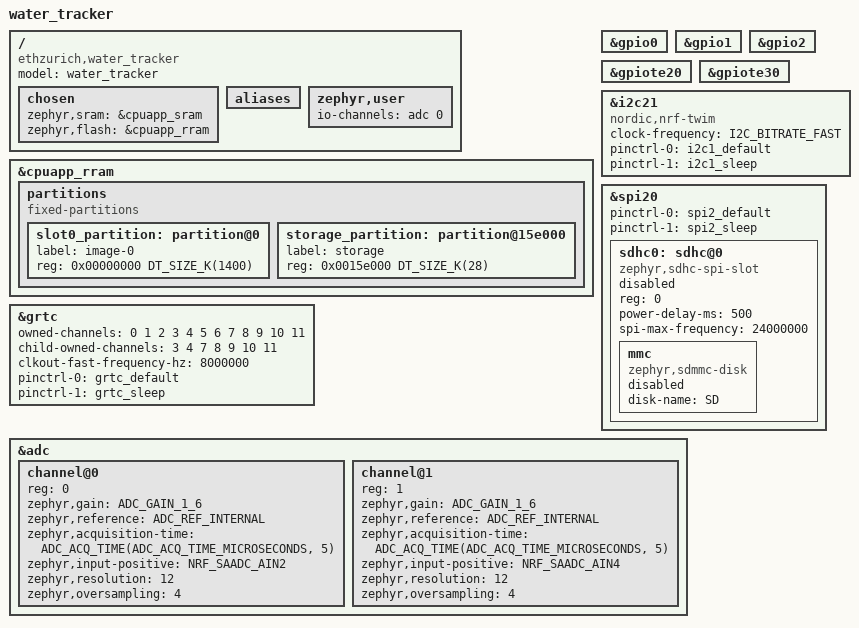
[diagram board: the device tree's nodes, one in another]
/*
 * Water sense board — ISP2454-LX (Nordic nRF54L15) + VL53L9CX + SD card.
 *
 * Migrated 2026-09-04 from Victor's hardware-model-v1 board file, for nRF
 * Connect SDK v3.3. The original is recoverable at commit ec65298.
 *
 * ---------------------------------------------------------------------------
 * WHAT SURVIVED UNCHANGED: every pin Victor assigned, the ADC configuration,
 * the BT_CTLR default, and the intent of the SPI/SD arrangement.
 *
 * WHAT CHANGED, and why:
 *   - hardware model v1 -> v2 (the reason nothing built under NCS 3.3)
 *   - nrf54L15_M33.dtsi -> nrf54l15_cpuapp.dtsi, and the SoC symbol with it
 *   - flash0/sram0 -> cpuapp_rram/cpuapp_sram; the nRF54L15 has RRAM
 *   - partitions resized from 512 KB to the full 1428 KB, MCUboot dropped
 *   - gpio1 and gpio2 enabled (where the pins actually are), gpio0 too
 *   - AP_CLK: 8 MHz on P0.00 from GRTC clkout-fast, not PWM
 *   - RTT console added, so the board can say something
 *   - sdhc0 disabled pending the chip-select decision — see the note on it
 *
 * PERIPHERAL INSTANCE NAMES ARE THE REMAINING GUESS. The nRF54L15 numbers by
 * power domain. i2c21 and spi20 below are chosen to match the pin domains
 * (P1 -> 20-series, P2 -> the fast domain), but if the build says a node does
 * not exist, diff against zephyr/boards/nordic/nrf54l15dk/ in the installed
 * SDK — that is the authority, and it settles every name here at once.
 * ---------------------------------------------------------------------------
 *
 * SPDX-License-Identifier: Apache-2.0
 */

/dts-v1/;

#include <nordic/nrf54l15_cpuapp.dtsi>
#include <zephyr/dt-bindings/adc/adc.h>
#include <zephyr/dt-bindings/gpio/gpio.h>
#include <zephyr/dt-bindings/i2c/i2c.h>
#include "water_sense_board_nrf54l15_cpuapp-pinctrl.dtsi"

/ {
	model = "water_tracker";
	compatible = "ethzurich,water_tracker";

	chosen {
		zephyr,sram = &cpuapp_sram;
		zephyr,flash = &cpuapp_rram;

		/*
		 * Console over SEGGER RTT, not a UART.
		 *
		 * No UART pins are assigned on this board and the pin budget is
		 * already committed, so RTT costs nothing and works over the
		 * J-Link that is attached anyway. Swap for a UART later if the
		 * pins appear.
		 *
		 * NO zephyr,code-partition: without MCUboot in the build it
		 * would link the image at a bootloader offset the chip never
		 * jumps to, which looks exactly like a dead board. Add it back
		 * together with sysbuild and MCUboot, not before.
		 */
	};

	aliases {
		/*
		 * watchdog0 = &wdt0 was in the original and is dropped: wdt0
		 * does not exist on this SoC (the instances are numbered by
		 * domain, wdt30/wdt31). Nothing referenced it. Re-add pointing
		 * at the real instance if a watchdog is wanted.
		 */
	};

	zephyr,user {
		io-channels = <&adc 0>;
	};
};

/* ---------------------------------------------------------------------------
 * Memory. 1428 KB is what the application core actually has — the remainder of
 * the nRF54L15's RRAM is reserved for the FLPR core. The previous table mapped
 * 512 KB of it and left the other two thirds stranded.
 *
 * No bootloader here, so the application gets everything up to the storage
 * area. Adding MCUboot later is a partition change and a rebuild, not a
 * redesign — the four-partition layout is in
 * docs/hardware/water-sense-board-review.md.
 * -------------------------------------------------------------------------*/
&cpuapp_rram {
	partitions {
		compatible = "fixed-partitions";
		#address-cells = <1>;
		#size-cells = <1>;

		slot0_partition: partition@0 {
			label = "image-0";
			reg = <0x00000000 DT_SIZE_K(1400)>;
		};

		storage_partition: partition@15e000 {
			label = "storage";
			reg = <0x0015e000 DT_SIZE_K(28)>;
		};
	};
};

/* All three ports enabled.
 *
 * gpio2 is the one that matters: chip select on P2.05 is driven in software
 * from the port file, and a software-driven pin needs the GPIO driver even
 * though pinctrl signals do not. gpio1 and gpio0 carry only pinctrl signals
 * (the I2C bus and AP_CLK respectively) and would work without this, but there
 * is no reason to leave ports off on a board still being brought up.
 */
&gpio0 {
	status = "okay";
};

&gpio1 {
	status = "okay";
};

&gpio2 {
	status = "okay";
};

&gpiote20 {
	status = "okay";
};

&gpiote30 {
	status = "okay";
};

/* ---------------------------------------------------------------------------
 * AP_CLK for the VL53L9CX — 8 MHz on P0.00, from the GRTC fast clock output.
 *
 * P0.13 was given first and is not a pin on this SoC (gpio0 has ngpios = <7>,
 * so P0.00..P0.06). Corrected to P0.00 by Victor. That correction also forces
 * the mechanism: PWM cannot drive port 0, so this is GRTC, not pwm20.
 *
 * WHY THIS IS BETTER THAN THE PWM IT REPLACES. From
 * zephyr/drivers/timer/nrf_grtc_timer.c:
 *
 *     grtc_div = base_frequency / (requested_frequency * 2)
 *     #error if requested > base / 2
 *
 * with base = pclk = 16 MHz. So the maximum fast-clock output is 8 MHz, and at
 * 8 MHz the divider is exactly 1. Our frequency is the top of the range and
 * lands on an integer divider — none of the COUNTERTOP-of-2 marginality that
 * made 8 MHz a stretch on a PWM.
 *
 * It is also the ONLY usable value: the next divider down gives 4 MHz, which
 * is below the sensor's 6 MHz minimum. The constraint picked the number again,
 * independently of the PWM reasoning that first arrived at it.
 *
 * ONE CONSEQUENCE FOR STAGE 4, and it is a real trade rather than a detail:
 * the GRTC clock output is configured once at boot and runs continuously.
 * Zephyr exposes no runtime gate for it, so AP_CLK can no longer be switched
 * off with the sensor power domain the way the driver was designed to. Either
 * accept an always-on 8 MHz output and measure what it costs, or move AP_CLK
 * to a P1/P2 pin on a PWM, which is gateable but marginal at 8 MHz. Worth
 * deciding with the Power Profiler rather than in advance.
 * -------------------------------------------------------------------------*/
&grtc {
	/* status = "okay" is not optional and is not about AP_CLK: the GRTC is
	 * this SoC's system timer, and the SoC dtsi ships it disabled. Without
	 * this line CONFIG_SYS_CLOCK_HW_CYCLES_PER_SEC is never defined and the
	 * build fails deep inside sys/clock.h with "operator '==' has no left
	 * operand", which names nothing useful. The original board file did not
	 * enable it either — it simply never got far enough to find out.
	 */
	status = "okay";

	/* Which of the 12 capture/compare channels this core owns, and which it
	 * lends to the FLPR core and to Zero Latency IRQs. The GRTC timer driver
	 * #errors without them. Values taken from Nordic's own
	 * nrf54l_05_10_15_cpuapp_common.dtsi — channels 7-11 for ZLI, 3-4 for
	 * FLPR — and worth revisiting only if the FLPR core is ever used here.
	 */
	owned-channels = <0 1 2 3 4 5 6 7 8 9 10 11>;
	child-owned-channels = <3 4 7 8 9 10 11>;

	clkout-fast-frequency-hz = <8000000>;
	pinctrl-0 = <&grtc_default>;
	pinctrl-1 = <&grtc_sleep>;
	pinctrl-names = "default", "sleep";
};

/* I2C: SCL P1.08, SDA P1.13. Instance renamed from i2c1, which does not exist
 * on this SoC.
 *
 * 400 kHz rather than the default 100 kHz: a full 54x42 VL53L9CX frame is
 * 14,842 bytes, which is ~404 ms at 400 kHz and ~1.6 s at 100 kHz.
 *
 * If the board has no external pull-ups on SDA/SCL, add bias-pull-up to the
 * pinctrl group — it is silent either way until the bus does not work.
 */
&i2c21 {
	status = "okay";
	compatible = "nordic,nrf-twim";
	clock-frequency = <I2C_BITRATE_FAST>;

	pinctrl-0 = <&i2c1_default>;
	pinctrl-1 = <&i2c1_sleep>;
	pinctrl-names = "default", "sleep";

	/* The VL53L9CX node is NOT here on purpose. It belongs in an
	 * application-level overlay, so this board file stays about the board
	 * and the sensor's configuration travels with the application that
	 * uses it.
	 */
};

/* SPI to the SD card: SCK P2.01, MOSI/SDI P2.04, MISO/SDO P2.02.
 * Instance renamed from spi2, which does not exist on this SoC.
 */
&spi20 {
	status = "okay";
	pinctrl-0 = <&spi2_default>;
	pinctrl-1 = <&spi2_sleep>;
	pinctrl-names = "default", "sleep";

	/*
	 * DISABLED PENDING A DECISION, not deleted.
	 *
	 * Chip select on P2.05 is driven in software from the port file. This
	 * node is Zephyr's SD-over-SPI stack, and `reg = <0>` means "SPI device
	 * 0" — it expects the controller's cs-gpios[0] to exist and drives it
	 * around every transfer. The two cannot both own the pin: manual
	 * toggling underneath Zephyr's produces glitches that read as card
	 * timeouts.
	 *
	 * So, one or the other:
	 *   - Zephyr's stack: add `cs-gpios = <&gpio2 5 GPIO_ACTIVE_LOW>;` to
	 *     this node's parent and set status = "okay" here.
	 *   - Port file owns CS: delete this node and talk to the card with raw
	 *     SPI transactions.
	 *
	 * Left disabled so the board builds and boots either way, and so the SD
	 * path cannot fail confusingly at runtime before the decision is made.
	 */
	sdhc0: sdhc@0 {
		status = "disabled";
		compatible = "zephyr,sdhc-spi-slot";
		reg = <0>;
		power-delay-ms = <500>;
		spi-max-frequency = <24000000>;
		mmc {
			/* disk-name is REQUIRED by zephyr,sdmmc-disk and was
			 * missing. This is what stopped the build, and it
			 * predates the migration — the original board file had
			 * the same gap, so it would have failed on any SDK.
			 * Note the parent is disabled but this child was not,
			 * and devicetree validates any node that is enabled.
			 */
			status = "disabled";
			compatible = "zephyr,sdmmc-disk";
			disk-name = "SD";
		};
	};
};

/* ADC — carried over from the original unchanged.
 * VERIFY that NRF_SAADC_AIN2 / AIN4 still name the intended pins: the nRF54L
 * family has its own SAADC input bindings and the numbering is not always the
 * same as earlier nRF parts.
 */
&adc {
	#address-cells = <1>;
	#size-cells = <0>;
	status = "okay";

	channel@0 {
		reg = <0>;
		zephyr,gain = "ADC_GAIN_1_6";
		zephyr,reference = "ADC_REF_INTERNAL";
		zephyr,acquisition-time = <ADC_ACQ_TIME(ADC_ACQ_TIME_MICROSECONDS, 5)>;
		zephyr,input-positive = <NRF_SAADC_AIN2>;
		zephyr,resolution = <12>;
		zephyr,oversampling = <4>;
	};

	channel@1 {
		reg = <1>;
		zephyr,gain = "ADC_GAIN_1_6";
		zephyr,reference = "ADC_REF_INTERNAL";
		zephyr,acquisition-time = <ADC_ACQ_TIME(ADC_ACQ_TIME_MICROSECONDS, 5)>;
		zephyr,input-positive = <NRF_SAADC_AIN4>;
		zephyr,resolution = <12>;
		zephyr,oversampling = <4>;
	};
};
